VERSION "1.0.0"

NS_ :

BS_:
BU_: BMS Motor Gateway

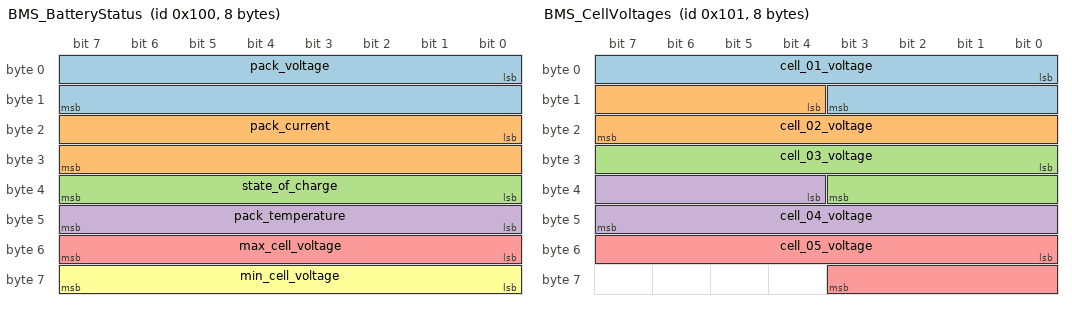
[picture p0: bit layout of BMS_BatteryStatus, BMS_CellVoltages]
BO_ 256 BMS_BatteryStatus: 8 BMS
 SG_ pack_voltage : 0|16@1+ (0.1,0) [0|800] "V" Gateway,Motor
 SG_ pack_current : 16|16@1- (0.1,0) [-400|400] "A" Gateway,Motor
 SG_ state_of_charge : 32|8@1+ (1,0) [0|100] "%" Gateway,Motor
 SG_ pack_temperature : 40|8@1- (1,-40) [-40|85] "C" Gateway
 SG_ max_cell_voltage : 48|8@1+ (0.02,0) [0|5] "V" Gateway
 SG_ min_cell_voltage : 56|8@1+ (0.02,0) [0|5] "V" Gateway

BO_ 257 BMS_CellVoltages: 8 BMS
 SG_ cell_01_voltage : 0|12@1+ (0.001,0) [0|5] "V" Gateway
 SG_ cell_02_voltage : 12|12@1+ (0.001,0) [0|5] "V" Gateway
 SG_ cell_03_voltage : 24|12@1+ (0.001,0) [0|5] "V" Gateway
 SG_ cell_04_voltage : 36|12@1+ (0.001,0) [0|5] "V" Gateway
 SG_ cell_05_voltage : 48|12@1+ (0.001,0) [0|5] "V" Gateway

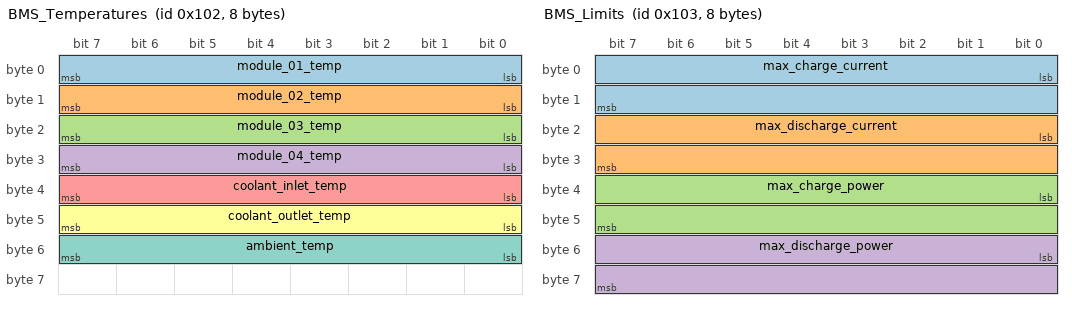
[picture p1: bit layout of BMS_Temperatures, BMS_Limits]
BO_ 258 BMS_Temperatures: 8 BMS
 SG_ module_01_temp : 0|8@1- (1,-40) [-40|125] "C" Gateway
 SG_ module_02_temp : 8|8@1- (1,-40) [-40|125] "C" Gateway
 SG_ module_03_temp : 16|8@1- (1,-40) [-40|125] "C" Gateway
 SG_ module_04_temp : 24|8@1- (1,-40) [-40|125] "C" Gateway
 SG_ coolant_inlet_temp : 32|8@1- (1,-40) [-40|125] "C" Gateway
 SG_ coolant_outlet_temp : 40|8@1- (1,-40) [-40|125] "C" Gateway
 SG_ ambient_temp : 48|8@1- (1,-40) [-40|125] "C" Gateway

BO_ 259 BMS_Limits: 8 BMS
 SG_ max_charge_current : 0|16@1+ (0.1,0) [0|400] "A" Motor
 SG_ max_discharge_current : 16|16@1+ (0.1,0) [0|800] "A" Motor
 SG_ max_charge_power : 32|16@1+ (0.1,0) [0|150] "kW" Motor
 SG_ max_discharge_power : 48|16@1+ (0.1,0) [0|300] "kW" Motor

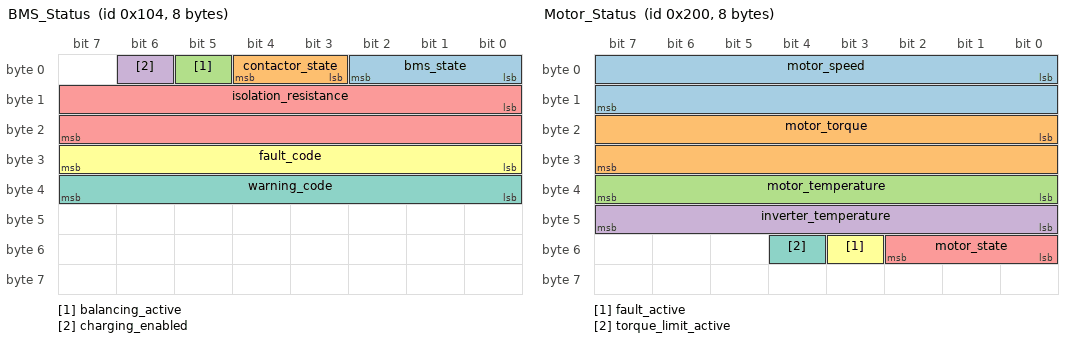
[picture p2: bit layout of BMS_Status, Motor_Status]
BO_ 260 BMS_Status: 8 BMS
 SG_ bms_state : 0|3@1+ (1,0) [0|7] "" Gateway
 SG_ contactor_state : 3|2@1+ (1,0) [0|3] "" Gateway
 SG_ balancing_active : 5|1@1+ (1,0) [0|1] "" Gateway
 SG_ charging_enabled : 6|1@1+ (1,0) [0|1] "" Gateway
 SG_ isolation_resistance : 8|16@1+ (1,0) [0|65535] "kOhm" Gateway
 SG_ fault_code : 24|8@1+ (1,0) [0|255] "" Gateway
 SG_ warning_code : 32|8@1+ (1,0) [0|255] "" Gateway

BO_ 261 BMS_CellDetail: 8 BMS
 SG_ cell_group M : 0|4@1+ (1,0) [0|15] "" Gateway
 SG_ cell_a_voltage m0 : 4|12@1+ (0.001,0) [0|5] "V" Gateway
 SG_ cell_b_voltage m0 : 16|12@1+ (0.001,0) [0|5] "V" Gateway
 SG_ cell_c_voltage m0 : 28|12@1+ (0.001,0) [0|5] "V" Gateway
 SG_ cell_d_voltage m0 : 40|12@1+ (0.001,0) [0|5] "V" Gateway
 SG_ cell_a_temp m1 : 4|8@1- (1,-40) [-40|125] "C" Gateway
 SG_ cell_b_temp m1 : 12|8@1- (1,-40) [-40|125] "C" Gateway
 SG_ cell_c_temp m1 : 20|8@1- (1,-40) [-40|125] "C" Gateway
 SG_ cell_d_temp m1 : 28|8@1- (1,-40) [-40|125] "C" Gateway
 SG_ balancing_target_cell m2 : 4|4@1+ (1,0) [0|15] "" Gateway
 SG_ balancing_target_voltage m2 : 8|12@1+ (0.001,0) [0|5] "V" Gateway
 SG_ balancing_active_mask m2 : 20|16@1+ (1,0) [0|65535] "" Gateway
 SG_ frame_counter : 56|8@1+ (1,0) [0|255] "" Gateway

BO_ 512 Motor_Status: 8 Motor
 SG_ motor_speed : 0|16@1- (1,-10000) [-10000|10000] "rpm" Gateway,BMS
 SG_ motor_torque : 16|16@1- (0.1,0) [-500|500] "Nm" Gateway,BMS
 SG_ motor_temperature : 32|8@1- (1,-40) [-40|200] "C" Gateway
 SG_ inverter_temperature : 40|8@1- (1,-40) [-40|125] "C" Gateway
 SG_ motor_state : 48|3@1+ (1,0) [0|7] "" Gateway,BMS
 SG_ fault_active : 51|1@1+ (1,0) [0|1] "" Gateway,BMS
 SG_ torque_limit_active : 52|1@1+ (1,0) [0|1] "" Gateway

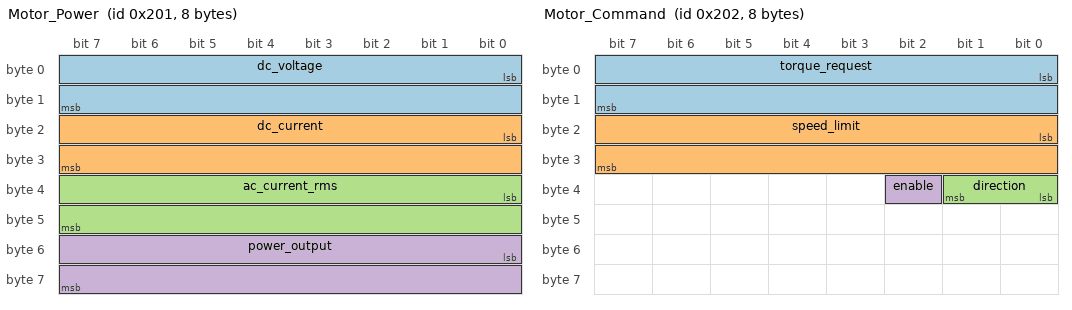
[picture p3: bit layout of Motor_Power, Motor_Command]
BO_ 513 Motor_Power: 8 Motor
 SG_ dc_voltage : 0|16@1+ (0.1,0) [0|800] "V" Gateway,BMS
 SG_ dc_current : 16|16@1- (0.1,0) [-800|800] "A" Gateway,BMS
 SG_ ac_current_rms : 32|16@1+ (0.1,0) [0|600] "A" Gateway
 SG_ power_output : 48|16@1- (0.1,0) [-300|300] "kW" Gateway,BMS

BO_ 514 Motor_Command: 8 Motor
 SG_ torque_request : 0|16@1- (0.1,0) [-500|500] "Nm" Motor
 SG_ speed_limit : 16|16@1+ (1,0) [0|15000] "rpm" Motor
 SG_ direction : 32|2@1+ (1,0) [0|2] "" Motor
 SG_ enable : 34|1@1+ (1,0) [0|1] "" Motor

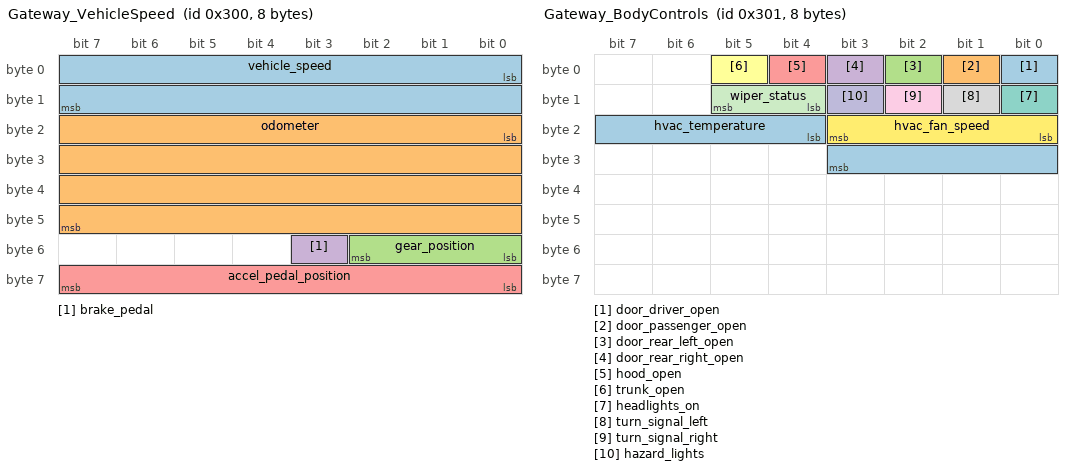
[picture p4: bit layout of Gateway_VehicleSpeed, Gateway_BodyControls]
BO_ 768 Gateway_VehicleSpeed: 8 Gateway
 SG_ vehicle_speed : 0|16@1+ (0.01,0) [0|300] "km/h" BMS,Motor
 SG_ odometer : 16|32@1+ (0.1,0) [0|999999] "km" BMS,Motor
 SG_ gear_position : 48|3@1+ (1,0) [0|5] "" BMS,Motor
 SG_ brake_pedal : 51|1@1+ (1,0) [0|1] "" Motor
 SG_ accel_pedal_position : 56|8@1+ (0.4,0) [0|100] "%" Motor

BO_ 769 Gateway_BodyControls: 8 Gateway
 SG_ door_driver_open : 0|1@1+ (1,0) [0|1] "" BMS
 SG_ door_passenger_open : 1|1@1+ (1,0) [0|1] "" BMS
 SG_ door_rear_left_open : 2|1@1+ (1,0) [0|1] "" BMS
 SG_ door_rear_right_open : 3|1@1+ (1,0) [0|1] "" BMS
 SG_ hood_open : 4|1@1+ (1,0) [0|1] "" BMS
 SG_ trunk_open : 5|1@1+ (1,0) [0|1] "" BMS
 SG_ headlights_on : 8|1@1+ (1,0) [0|1] "" BMS
 SG_ turn_signal_left : 9|1@1+ (1,0) [0|1] "" BMS
 SG_ turn_signal_right : 10|1@1+ (1,0) [0|1] "" BMS
 SG_ hazard_lights : 11|1@1+ (1,0) [0|1] "" BMS
 SG_ wiper_status : 12|2@1+ (1,0) [0|3] "" BMS
 SG_ hvac_fan_speed : 16|4@1+ (1,0) [0|15] "" BMS
 SG_ hvac_temperature : 20|8@1+ (0.5,0) [0|50] "C" BMS

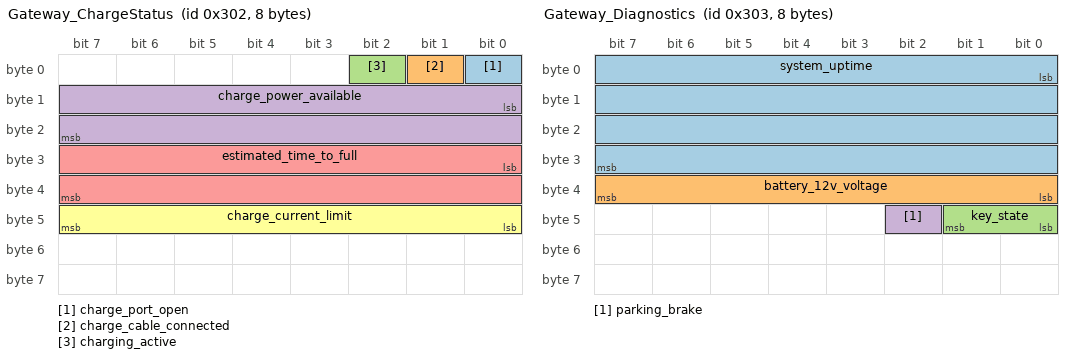
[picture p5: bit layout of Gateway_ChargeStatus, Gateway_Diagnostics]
BO_ 770 Gateway_ChargeStatus: 8 Gateway
 SG_ charge_port_open : 0|1@1+ (1,0) [0|1] "" BMS
 SG_ charge_cable_connected : 1|1@1+ (1,0) [0|1] "" BMS
 SG_ charging_active : 2|1@1+ (1,0) [0|1] "" BMS
 SG_ charge_power_available : 8|16@1+ (0.1,0) [0|350] "kW" BMS
 SG_ estimated_time_to_full : 24|16@1+ (1,0) [0|1440] "min" BMS
 SG_ charge_current_limit : 40|8@1+ (1,0) [0|80] "A" BMS

BO_ 771 Gateway_Diagnostics: 8 Gateway
 SG_ system_uptime : 0|32@1+ (1,0) [0|4294967295] "s" BMS,Motor
 SG_ battery_12v_voltage : 32|8@1+ (0.1,0) [0|25] "V" BMS,Motor
 SG_ key_state : 40|2@1+ (1,0) [0|3] "" BMS,Motor
 SG_ parking_brake : 42|1@1+ (1,0) [0|1] "" Motor

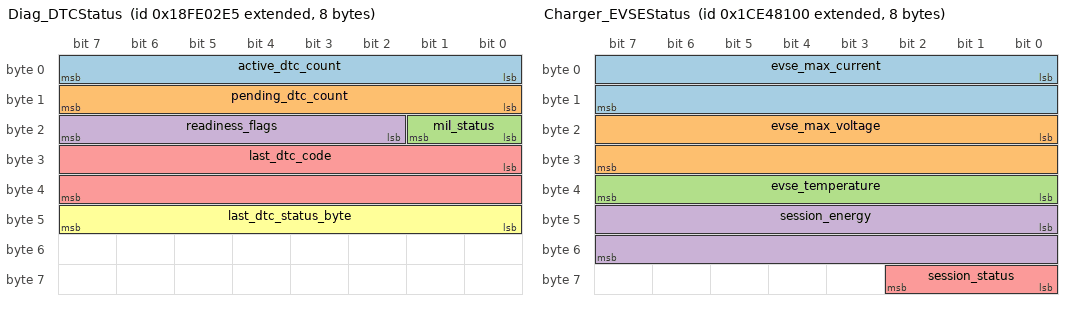
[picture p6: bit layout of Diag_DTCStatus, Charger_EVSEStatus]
BO_ 2566783717 Diag_DTCStatus: 8 Gateway
 SG_ active_dtc_count : 0|8@1+ (1,0) [0|255] "" BMS,Motor
 SG_ pending_dtc_count : 8|8@1+ (1,0) [0|255] "" BMS,Motor
 SG_ mil_status : 16|2@1+ (1,0) [0|3] "" BMS,Motor
 SG_ readiness_flags : 18|6@1+ (1,0) [0|63] "" BMS,Motor
 SG_ last_dtc_code : 24|16@1+ (1,0) [0|65535] "" BMS,Motor
 SG_ last_dtc_status_byte : 40|8@1+ (1,0) [0|255] "" BMS,Motor

BO_ 2632220928 Charger_EVSEStatus: 8 Gateway
 SG_ evse_max_current : 0|16@1+ (0.1,0) [0|350] "A" BMS
 SG_ evse_max_voltage : 16|16@1+ (0.1,0) [0|1000] "V" BMS
 SG_ evse_temperature : 32|8@1- (1,-40) [-40|125] "C" BMS
 SG_ session_energy : 40|16@1+ (0.01,0) [0|500] "kWh" BMS
 SG_ session_status : 56|3@1+ (1,0) [0|7] "" BMS

CM_ BU_ BMS "Battery Management System - monitors and controls the high-voltage battery pack";
CM_ BU_ Motor "Motor Controller - controls the electric drive motor and inverter";
CM_ BU_ Gateway "Gateway ECU - aggregates vehicle body controls and provides diagnostic data";

CM_ BO_ 256 "Primary battery pack status and state of charge";
CM_ BO_ 257 "Individual cell voltages for battery monitoring";
CM_ BO_ 258 "Temperature sensors throughout battery pack and cooling system";
CM_ BO_ 259 "Current battery charge and discharge limits";
CM_ BO_ 260 "BMS operational state and fault information";
CM_ BO_ 512 "Motor operational status and measurements";
CM_ BO_ 513 "Motor electrical measurements and power output";
CM_ BO_ 514 "Motor control commands from vehicle controller";
CM_ BO_ 768 "Vehicle speed and odometer information";
CM_ BO_ 769 "Body control module status (doors, lights, HVAC)";
CM_ BO_ 770 "Charging system status and parameters";
CM_ BO_ 771 "System diagnostics and health monitoring";
CM_ BO_ 2566783717 "Extended-ID J1939-style diagnostic trouble code status (29-bit)";
CM_ BO_ 2632220928 "Extended-ID EVSE / charge station status (29-bit)";

BA_DEF_ "BusType" STRING ;
BA_DEF_ BO_ "GenMsgCycleTime" INT 0 10000;

BA_DEF_DEF_ "BusType" "CAN";
BA_DEF_DEF_ "GenMsgCycleTime" 0;

BA_ "GenMsgCycleTime" BO_ 256 100;
BA_ "GenMsgCycleTime" BO_ 257 1000;
BA_ "GenMsgCycleTime" BO_ 258 500;
BA_ "GenMsgCycleTime" BO_ 259 200;
BA_ "GenMsgCycleTime" BO_ 260 100;
BA_ "GenMsgCycleTime" BO_ 261 250;
BA_ "GenMsgCycleTime" BO_ 512 50;
BA_ "GenMsgCycleTime" BO_ 513 100;
BA_ "GenMsgCycleTime" BO_ 514 20;
BA_ "GenMsgCycleTime" BO_ 768 100;
BA_ "GenMsgCycleTime" BO_ 769 200;
BA_ "GenMsgCycleTime" BO_ 770 500;
BA_ "GenMsgCycleTime" BO_ 771 1000;
BA_ "GenMsgCycleTime" BO_ 2566783717 1000;
BA_ "GenMsgCycleTime" BO_ 2632220928 500;

VAL_ 260 bms_state 0 "INIT" 1 "IDLE" 2 "PRECHARGE" 3 "READY" 4 "CHARGING" 5 "FAULT" 6 "EMERGENCY";
VAL_ 260 contactor_state 0 "OPEN" 1 "PRECHARGE" 2 "CLOSED" 3 "FAULT";
VAL_ 261 cell_group 0 "VOLTAGES_1_4" 1 "TEMPERATURES_1_4" 2 "BALANCING";
VAL_ 257 cell_01_voltage 4095 "SNA";
VAL_ 257 cell_02_voltage 4095 "SNA";
VAL_ 257 cell_03_voltage 4095 "SNA";
VAL_ 257 cell_04_voltage 4095 "SNA";
VAL_ 257 cell_05_voltage 4095 "SNA";
VAL_ 261 cell_a_voltage 4095 "SNA";
VAL_ 261 cell_b_voltage 4095 "SNA";
VAL_ 261 cell_c_voltage 4095 "SNA";
VAL_ 261 cell_d_voltage 4095 "SNA";
VAL_ 261 balancing_target_voltage 4095 "SNA";
VAL_ 512 motor_state 0 "OFF" 1 "IDLE" 2 "READY" 3 "RUNNING" 4 "REGEN" 5 "FAULT";
VAL_ 514 direction 0 "NEUTRAL" 1 "FORWARD" 2 "REVERSE";
VAL_ 768 gear_position 0 "PARK" 1 "REVERSE" 2 "NEUTRAL" 3 "DRIVE" 4 "LOW" 5 "SPORT";
VAL_ 769 wiper_status 0 "OFF" 1 "INTERMITTENT" 2 "LOW" 3 "HIGH";
VAL_ 771 key_state 0 "OFF" 1 "ACC" 2 "ON" 3 "START";
VAL_ 2566783717 mil_status 0 "OFF" 1 "ON" 2 "BLINK" 3 "INVALID";
VAL_ 2632220928 session_status 0 "IDLE" 1 "CONNECTED" 2 "AUTHORIZED" 3 "CHARGING" 4 "PAUSED" 5 "COMPLETE" 6 "FAULT" 7 "INVALID";
